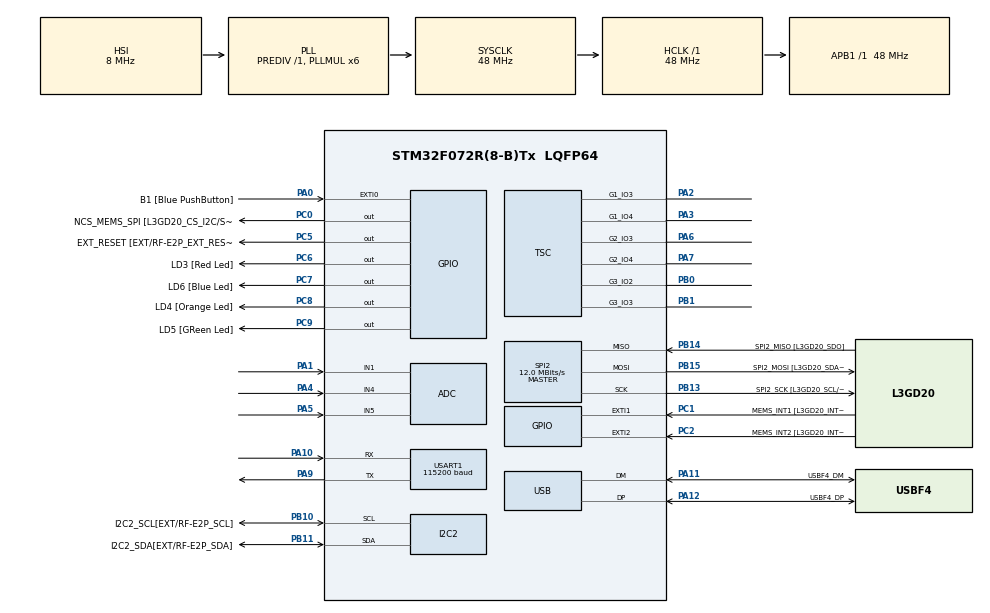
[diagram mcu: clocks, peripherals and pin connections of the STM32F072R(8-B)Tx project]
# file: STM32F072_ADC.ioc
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ADC.ClockPrescaler=ADC_CLOCK_ASYNC_DIV1
ADC.ContinuousConvMode=DISABLE
ADC.DMAContinuousRequests=DISABLE
ADC.DiscontinuousConvMode=DISABLE
ADC.EOCSelection=ADC_EOC_SINGLE_CONV
ADC.EnableAnalogWatchDog=false
ADC.ExternalTrigConv=ADC_SOFTWARE_START
ADC.SamplingTime=ADC_SAMPLETIME_239CYCLES_5
ADC.ScanConvMode=ADC_SCAN_DIRECTION_FORWARD
Dma.ADC.0.Direction=DMA_PERIPH_TO_MEMORY
Dma.ADC.0.Instance=DMA1_Channel1
Dma.ADC.0.MemDataAlignment=DMA_MDATAALIGN_WORD
Dma.ADC.0.MemInc=DMA_MINC_ENABLE
Dma.ADC.0.Mode=DMA_CIRCULAR
Dma.ADC.0.PeriphDataAlignment=DMA_PDATAALIGN_WORD
Dma.ADC.0.PeriphInc=DMA_PINC_DISABLE
Dma.ADC.0.Priority=DMA_PRIORITY_LOW
Dma.Request0=ADC
I2C2.Timing=0x20303E5D
Mcu.Family=STM32F0
Mcu.Name=STM32F072R(8-B)Tx
Mcu.Package=LQFP64
NVIC.DMA1_Channel1_IRQn=true\:0\:0\:false\:false\:true\:false\:true
PA0.GPIO_Label=B1 [Blue PushButton]
PA0.GPIO_ModeDefaultEXTI=GPIO_MODE_EVT_RISING
PA0.Signal=GPXTI0
PA1.Mode=IN1
PA1.Signal=ADC_IN1
PA10.Mode=Asynchronous
PA10.Signal=USART1_RX
PA11.GPIO_Label=USBF4_DM
PA11.Mode=Device
PA11.Signal=USB_DM
PA12.GPIO_Label=USBF4_DP
PA12.Mode=Device
PA12.Signal=USB_DP
PA13.GPIO_Label=SWDIO
PA13.Mode=Serial_Wire
PA13.Signal=SYS_SWDIO
PA14.GPIO_Label=SWCLK
PA14.Mode=Serial_Wire
PA14.Signal=SYS_SWCLK
PA2.Mode=G1_IO3-Channel
PA2.Signal=TSC_G1_IO3
PA3.Mode=G1_IO4-Sampling
PA3.Signal=TSC_G1_IO4
PA4.Mode=IN4
PA4.Signal=ADC_IN4
PA5.Mode=IN5
PA5.Signal=ADC_IN5
PA6.Mode=G2_IO3-Channel
PA6.Signal=TSC_G2_IO3
PA7.Mode=G2_IO4-Sampling
PA7.Signal=TSC_G2_IO4
PA9.Mode=Asynchronous
PA9.Signal=USART1_TX
PB0.Mode=G3_IO2-Channel
PB0.Signal=TSC_G3_IO2
PB1.Mode=G3_IO3-Sampling
PB1.Signal=TSC_G3_IO3
PB10.GPIO_Label=I2C2_SCL[EXT/RF-E2P_SCL]
PB10.GPIO_Pu=GPIO_PULLUP
PB10.Mode=I2C
PB10.Signal=I2C2_SCL
PB11.GPIO_Label=I2C2_SDA[EXT/RF-E2P_SDA]
PB11.GPIO_Pu=GPIO_PULLUP
PB11.Mode=I2C
PB11.Signal=I2C2_SDA
PB13.GPIO_Label=SPI2_SCK [L3GD20_SCL/SPC]
PB13.Mode=Full_Duplex_Master
PB13.Signal=SPI2_SCK
PB14.GPIO_Label=SPI2_MISO [L3GD20_SDO]
PB14.Mode=Full_Duplex_Master
PB14.Signal=SPI2_MISO
PB15.GPIO_Label=SPI2_MOSI [L3GD20_SDA/SDI]
PB15.Mode=Full_Duplex_Master
PB15.Signal=SPI2_MOSI
PC0.GPIO_Label=NCS_MEMS_SPI [L3GD20_CS_I2C/SPI]
PC0.Signal=GPIO_Output
PC1.GPIO_Label=MEMS_INT1 [L3GD20_INT1]
PC1.GPIO_ModeDefaultEXTI=GPIO_MODE_EVT_RISING
PC1.Signal=GPXTI1
PC2.GPIO_Label=MEMS_INT2 [L3GD20_INT2]
PC2.GPIO_ModeDefaultEXTI=GPIO_MODE_EVT_RISING
PC2.Signal=GPXTI2
PC5.GPIO_Label=EXT_RESET [EXT/RF-E2P_EXT_RESET]
PC5.Signal=GPIO_Output
PC6.GPIO_Label=LD3 [Red Led]
PC6.Signal=GPIO_Output
PC7.GPIO_Label=LD6 [Blue Led]
PC7.Signal=GPIO_Output
PC8.GPIO_Label=LD4 [Orange Led]
PC8.Signal=GPIO_Output
PC9.GPIO_Label=LD5 [GReen Led]
PC9.Signal=GPIO_Output
ProjectManager.HeapSize=0x200
ProjectManager.StackSize=0x400
ProjectManager.TargetToolchain=STM32CubeIDE
RCC.AHBFreq_Value=48000000
RCC.APB1Freq_Value=48000000
RCC.APB1TimFreq_Value=48000000
RCC.HCLKFreq_Value=48000000
RCC.PLLMUL=RCC_PLL_MUL6
RCC.SYSCLKFreq_VALUE=48000000
RCC.SYSCLKSource=RCC_SYSCLKSOURCE_PLLCLK
SPI2.BaudRatePrescaler=SPI_BAUDRATEPRESCALER_4
SPI2.CalculateBaudRate=12.0 MBits/s
SPI2.Direction=SPI_DIRECTION_2LINES
SPI2.Mode=SPI_MODE_MASTER
SPI2.VirtualType=VM_MASTER
USART1.BaudRate=115200
USART1.VirtualMode-Asynchronous=VM_ASYNC
USB.phy_itface=PCD_PHY_EMBEDDED
USB.speed=PCD_SPEED_FULL
VP_ADC_TempSens_Input.Mode=IN-TempSens
board=STM32F072B-DISCO

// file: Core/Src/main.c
/* USER CODE BEGIN Header */
/**
  ******************************************************************************
  * @file           : main.c
  * @brief          : Main program body
  ******************************************************************************
  * @attention
  *
  * <h2><center>&copy; Copyright (c) 2021 STMicroelectronics.
  * All rights reserved.</center></h2>
  *
  * This software component is licensed by ST under BSD 3-Clause license,
  * the "License"; You may not use this file except in compliance with the
  * License. You may obtain a copy of the License at:
  *                        opensource.org/licenses/BSD-3-Clause
  *
  ******************************************************************************
  */
/* USER CODE END Header */
#include "main.h"

/* USER CODE BEGIN Includes */
#include "stdio.h"
#include "stdint.h"
/* USER CODE END Includes */

/* USER CODE BEGIN PD */
#define MAX_UART_MSG_SIZE         80
#define NUM_OF_USED_ADC_CHANNELS  4
/* USER CODE END PD */

ADC_HandleTypeDef hadc;
DMA_HandleTypeDef hdma_adc;

I2C_HandleTypeDef hi2c2;

SPI_HandleTypeDef hspi2;

TSC_HandleTypeDef htsc;

UART_HandleTypeDef huart1;

PCD_HandleTypeDef hpcd_USB_FS;

void SystemClock_Config(void);
static void MX_GPIO_Init(void);
static void MX_I2C2_Init(void);
static void MX_SPI2_Init(void);
static void MX_TSC_Init(void);
static void MX_DMA_Init(void);
static void MX_ADC_Init(void);
static void MX_USART1_UART_Init(void);
static void MX_USB_PCD_Init(void);

int main(void)
{
  /* USER CODE BEGIN 1 */
   unsigned char testString[]               = "Hello World!\r\n";
   char uartBuffer[MAX_UART_MSG_SIZE]       = { 0 };
   uint32_t adcRaw[4]                       = { 0 };
  /* USER CODE END 1 */

  /* MCU Configuration--------------------------------------------------------*/

  /* Reset of all peripherals, Initializes the Flash interface and the Systick. */
  HAL_Init();

  /* Configure the system clock */
  SystemClock_Config();

  /* Initialize all configured peripherals */
  MX_GPIO_Init();
  MX_I2C2_Init();
  MX_SPI2_Init();
  MX_TSC_Init();
  MX_DMA_Init();
  MX_ADC_Init();
  MX_USART1_UART_Init();
  MX_USB_PCD_Init();
  /* USER CODE BEGIN 2 */
  HAL_UART_Transmit(&huart1, testString, sizeof(testString), 100);
  /* USER CODE END 2 */

  /* Infinite loop */
  /* USER CODE BEGIN WHILE */
  while (1)
  {
    HAL_ADC_Start_DMA(&hadc, adcRaw, 4);
    snprintf(uartBuffer, MAX_UART_MSG_SIZE, "adc raw values: %lu %lu %lu %lu\r\n", adcRaw[0], adcRaw[1], adcRaw[2], adcRaw[3]);
    HAL_UART_Transmit(&huart1, (uint8_t*)uartBuffer, sizeof(uartBuffer), 100);
    HAL_Delay(100);
    /* USER CODE END WHILE */

  }
}

void SystemClock_Config(void)
{
  RCC_OscInitTypeDef RCC_OscInitStruct = {0};
  RCC_ClkInitTypeDef RCC_ClkInitStruct = {0};
  RCC_PeriphCLKInitTypeDef PeriphClkInit = {0};

  /** Initializes the RCC Oscillators according to the specified parameters
  * in the RCC_OscInitTypeDef structure.
  */
  RCC_OscInitStruct.OscillatorType = RCC_OSCILLATORTYPE_HSI|RCC_OSCILLATORTYPE_HSI14
                              |RCC_OSCILLATORTYPE_HSI48;
  RCC_OscInitStruct.HSIState = RCC_HSI_ON;
  RCC_OscInitStruct.HSI48State = RCC_HSI48_ON;
  RCC_OscInitStruct.HSI14State = RCC_HSI14_ON;
  RCC_OscInitStruct.HSICalibrationValue = RCC_HSICALIBRATION_DEFAULT;
  RCC_OscInitStruct.HSI14CalibrationValue = 16;
  RCC_OscInitStruct.PLL.PLLState = RCC_PLL_ON;
  RCC_OscInitStruct.PLL.PLLSource = RCC_PLLSOURCE_HSI;
  RCC_OscInitStruct.PLL.PLLMUL = RCC_PLL_MUL6;
  RCC_OscInitStruct.PLL.PREDIV = RCC_PREDIV_DIV1;
  if (HAL_RCC_OscConfig(&RCC_OscInitStruct) != HAL_OK)
  {
    Error_Handler();
  }
  /** Initializes the CPU, AHB and APB buses clocks
  */
  RCC_ClkInitStruct.ClockType = RCC_CLOCKTYPE_HCLK|RCC_CLOCKTYPE_SYSCLK
                              |RCC_CLOCKTYPE_PCLK1;
  RCC_ClkInitStruct.SYSCLKSource = RCC_SYSCLKSOURCE_PLLCLK;
  RCC_ClkInitStruct.AHBCLKDivider = RCC_SYSCLK_DIV1;
  RCC_ClkInitStruct.APB1CLKDivider = RCC_HCLK_DIV1;

  if (HAL_RCC_ClockConfig(&RCC_ClkInitStruct, FLASH_LATENCY_1) != HAL_OK)
  {
    Error_Handler();
  }
  PeriphClkInit.PeriphClockSelection = RCC_PERIPHCLK_USB|RCC_PERIPHCLK_USART1;
  PeriphClkInit.Usart1ClockSelection = RCC_USART1CLKSOURCE_PCLK1;
  PeriphClkInit.UsbClockSelection = RCC_USBCLKSOURCE_HSI48;

  if (HAL_RCCEx_PeriphCLKConfig(&PeriphClkInit) != HAL_OK)
  {
    Error_Handler();
  }
}

static void MX_ADC_Init(void)
{

  ADC_ChannelConfTypeDef sConfig = {0};

  /** Configure the global features of the ADC (Clock, Resolution, Data Alignment and number of conversion)
  */
  hadc.Instance = ADC1;
  hadc.Init.ClockPrescaler = ADC_CLOCK_ASYNC_DIV1;
  hadc.Init.Resolution = ADC_RESOLUTION_12B;
  hadc.Init.DataAlign = ADC_DATAALIGN_RIGHT;
  hadc.Init.ScanConvMode = ADC_SCAN_DIRECTION_FORWARD;
  hadc.Init.EOCSelection = ADC_EOC_SINGLE_CONV;
  hadc.Init.LowPowerAutoWait = DISABLE;
  hadc.Init.LowPowerAutoPowerOff = DISABLE;
  hadc.Init.ContinuousConvMode = DISABLE;
  hadc.Init.DiscontinuousConvMode = DISABLE;
  hadc.Init.ExternalTrigConv = ADC_SOFTWARE_START;
  hadc.Init.ExternalTrigConvEdge = ADC_EXTERNALTRIGCONVEDGE_NONE;
  hadc.Init.DMAContinuousRequests = DISABLE;
  hadc.Init.Overrun = ADC_OVR_DATA_PRESERVED;
  if (HAL_ADC_Init(&hadc) != HAL_OK)
  {
    Error_Handler();
  }
  /** Configure for the selected ADC regular channel to be converted.
  */
  sConfig.Channel = ADC_CHANNEL_1;
  sConfig.Rank = ADC_RANK_CHANNEL_NUMBER;
  sConfig.SamplingTime = ADC_SAMPLETIME_239CYCLES_5;
  if (HAL_ADC_ConfigChannel(&hadc, &sConfig) != HAL_OK)
  {
    Error_Handler();
  }
  /** Configure for the selected ADC regular channel to be converted.
  */
  sConfig.Channel = ADC_CHANNEL_4;
  if (HAL_ADC_ConfigChannel(&hadc, &sConfig) != HAL_OK)
  {
    Error_Handler();
  }
  /** Configure for the selected ADC regular channel to be converted.
  */
  sConfig.Channel = ADC_CHANNEL_5;
  if (HAL_ADC_ConfigChannel(&hadc, &sConfig) != HAL_OK)
  {
    Error_Handler();
  }
  /** Configure for the selected ADC regular channel to be converted.
  */
  sConfig.Channel = ADC_CHANNEL_TEMPSENSOR;
  if (HAL_ADC_ConfigChannel(&hadc, &sConfig) != HAL_OK)
  {
    Error_Handler();
  }

}

static void MX_I2C2_Init(void)
{

  hi2c2.Instance = I2C2;
  hi2c2.Init.Timing = 0x20303E5D;
  hi2c2.Init.OwnAddress1 = 0;
  hi2c2.Init.AddressingMode = I2C_ADDRESSINGMODE_7BIT;
  hi2c2.Init.DualAddressMode = I2C_DUALADDRESS_DISABLE;
  hi2c2.Init.OwnAddress2 = 0;
  hi2c2.Init.OwnAddress2Masks = I2C_OA2_NOMASK;
  hi2c2.Init.GeneralCallMode = I2C_GENERALCALL_DISABLE;
  hi2c2.Init.NoStretchMode = I2C_NOSTRETCH_DISABLE;
  if (HAL_I2C_Init(&hi2c2) != HAL_OK)
  {
    Error_Handler();
  }
  /** Configure Analogue filter
  */
  if (HAL_I2CEx_ConfigAnalogFilter(&hi2c2, I2C_ANALOGFILTER_ENABLE) != HAL_OK)
  {
    Error_Handler();
  }
  /** Configure Digital filter
  */
  if (HAL_I2CEx_ConfigDigitalFilter(&hi2c2, 0) != HAL_OK)
  {
    Error_Handler();
  }

}

static void MX_SPI2_Init(void)
{

  /* SPI2 parameter configuration*/
  hspi2.Instance = SPI2;
  hspi2.Init.Mode = SPI_MODE_MASTER;
  hspi2.Init.Direction = SPI_DIRECTION_2LINES;
  hspi2.Init.DataSize = SPI_DATASIZE_4BIT;
  hspi2.Init.CLKPolarity = SPI_POLARITY_LOW;
  hspi2.Init.CLKPhase = SPI_PHASE_1EDGE;
  hspi2.Init.NSS = SPI_NSS_SOFT;
  hspi2.Init.BaudRatePrescaler = SPI_BAUDRATEPRESCALER_4;
  hspi2.Init.FirstBit = SPI_FIRSTBIT_MSB;
  hspi2.Init.TIMode = SPI_TIMODE_DISABLE;
  hspi2.Init.CRCCalculation = SPI_CRCCALCULATION_DISABLE;
  hspi2.Init.CRCPolynomial = 7;
  hspi2.Init.CRCLength = SPI_CRC_LENGTH_DATASIZE;
  hspi2.Init.NSSPMode = SPI_NSS_PULSE_ENABLE;
  if (HAL_SPI_Init(&hspi2) != HAL_OK)
  {
    Error_Handler();
  }

}

static void MX_TSC_Init(void)
{

  /** Configure the TSC peripheral
  */
  htsc.Instance = TSC;
  htsc.Init.CTPulseHighLength = TSC_CTPH_2CYCLES;
  htsc.Init.CTPulseLowLength = TSC_CTPL_2CYCLES;
  htsc.Init.SpreadSpectrum = DISABLE;
  htsc.Init.SpreadSpectrumDeviation = 1;
  htsc.Init.SpreadSpectrumPrescaler = TSC_SS_PRESC_DIV1;
  htsc.Init.PulseGeneratorPrescaler = TSC_PG_PRESC_DIV4;
  htsc.Init.MaxCountValue = TSC_MCV_8191;
  htsc.Init.IODefaultMode = TSC_IODEF_OUT_PP_LOW;
  htsc.Init.SynchroPinPolarity = TSC_SYNC_POLARITY_FALLING;
  htsc.Init.AcquisitionMode = TSC_ACQ_MODE_NORMAL;
  htsc.Init.MaxCountInterrupt = DISABLE;
  htsc.Init.ChannelIOs = TSC_GROUP1_IO3|TSC_GROUP2_IO3|TSC_GROUP3_IO2;
  htsc.Init.ShieldIOs = 0;
  htsc.Init.SamplingIOs = TSC_GROUP1_IO4|TSC_GROUP2_IO4|TSC_GROUP3_IO3;
  if (HAL_TSC_Init(&htsc) != HAL_OK)
  {
    Error_Handler();
  }

}

static void MX_USART1_UART_Init(void)
{

  huart1.Instance = USART1;
  huart1.Init.BaudRate = 115200;
  huart1.Init.WordLength = UART_WORDLENGTH_8B;
  huart1.Init.StopBits = UART_STOPBITS_1;
  huart1.Init.Parity = UART_PARITY_NONE;
  huart1.Init.Mode = UART_MODE_TX_RX;
  huart1.Init.HwFlowCtl = UART_HWCONTROL_NONE;
  huart1.Init.OverSampling = UART_OVERSAMPLING_16;
  huart1.Init.OneBitSampling = UART_ONE_BIT_SAMPLE_DISABLE;
  huart1.AdvancedInit.AdvFeatureInit = UART_ADVFEATURE_NO_INIT;
  if (HAL_UART_Init(&huart1) != HAL_OK)
  {
    Error_Handler();
  }

}

static void MX_USB_PCD_Init(void)
{

  hpcd_USB_FS.Instance = USB;
  hpcd_USB_FS.Init.dev_endpoints = 8;
  hpcd_USB_FS.Init.speed = PCD_SPEED_FULL;
  hpcd_USB_FS.Init.phy_itface = PCD_PHY_EMBEDDED;
  hpcd_USB_FS.Init.low_power_enable = DISABLE;
  hpcd_USB_FS.Init.lpm_enable = DISABLE;
  hpcd_USB_FS.Init.battery_charging_enable = DISABLE;
  if (HAL_PCD_Init(&hpcd_USB_FS) != HAL_OK)
  {
    Error_Handler();
  }

}

static void MX_DMA_Init(void)
{

  /* DMA controller clock enable */
  __HAL_RCC_DMA1_CLK_ENABLE();

  /* DMA interrupt init */
  /* DMA1_Channel1_IRQn interrupt configuration */
  HAL_NVIC_SetPriority(DMA1_Channel1_IRQn, 0, 0);
  HAL_NVIC_EnableIRQ(DMA1_Channel1_IRQn);

}

static void MX_GPIO_Init(void)
{
  GPIO_InitTypeDef GPIO_InitStruct = {0};

  /* GPIO Ports Clock Enable */
  __HAL_RCC_GPIOC_CLK_ENABLE();
  __HAL_RCC_GPIOA_CLK_ENABLE();
  __HAL_RCC_GPIOB_CLK_ENABLE();

  /*Configure GPIO pin Output Level */
  HAL_GPIO_WritePin(GPIOC, NCS_MEMS_SPI_Pin|EXT_RESET_Pin|LD3_Pin|LD6_Pin
                          |LD4_Pin|LD5_Pin, GPIO_PIN_RESET);

  /*Configure GPIO pins : NCS_MEMS_SPI_Pin EXT_RESET_Pin LD3_Pin LD6_Pin
                           LD4_Pin LD5_Pin */
  GPIO_InitStruct.Pin = NCS_MEMS_SPI_Pin|EXT_RESET_Pin|LD3_Pin|LD6_Pin
                          |LD4_Pin|LD5_Pin;
  GPIO_InitStruct.Mode = GPIO_MODE_OUTPUT_PP;
  GPIO_InitStruct.Pull = GPIO_NOPULL;
  GPIO_InitStruct.Speed = GPIO_SPEED_FREQ_LOW;
  HAL_GPIO_Init(GPIOC, &GPIO_InitStruct);

  /*Configure GPIO pins : MEMS_INT1_Pin MEMS_INT2_Pin */
  GPIO_InitStruct.Pin = MEMS_INT1_Pin|MEMS_INT2_Pin;
  GPIO_InitStruct.Mode = GPIO_MODE_EVT_RISING;
  GPIO_InitStruct.Pull = GPIO_NOPULL;
  HAL_GPIO_Init(GPIOC, &GPIO_InitStruct);

  /*Configure GPIO pin : B1_Pin */
  GPIO_InitStruct.Pin = B1_Pin;
  GPIO_InitStruct.Mode = GPIO_MODE_EVT_RISING;
  GPIO_InitStruct.Pull = GPIO_NOPULL;
  HAL_GPIO_Init(B1_GPIO_Port, &GPIO_InitStruct);

}

void Error_Handler(void)
{
  __disable_irq();
  while (1)
  {
  }
}

/************************ (C) COPYRIGHT STMicroelectronics *****END OF FILE****/
